AUTOSAR XML (schema 4.0)
standard types defined: float32, float64, sint16, sint32, sint8, uint16, uint32, uint8, void, boolean
package /ImplDataTypes
  4 x impl type, all with category=TYPE_REFERENCE, type-emitter=RTE:
    Impl_MultiStateBtnType: implementation-data-type=uint8
    Impl_SensorPostionType: implementation-data-type=uint32
    Impl_SensorWeightType: implementation-data-type=uint32
    Impl_StepMotorStepType: implementation-data-type=uint8
package /MappingSets
  data type mapping set MappingSet
package /PortInterfaces/ClientServer
  client server interface CsIf_PostionSensor
    operation Opr_GetPostion
      arg Arg_position: type=Impl_SensorPostionType, direction=OUT
  client server interface CsIf_StepMotor
    operation Opr_Move
      arg Arg_step: type=Impl_StepMotorStepType, direction=IN
  client server interface CsIf_WeightSensor
    operation Opr_GetWeight
      arg Arg_Weight: type=Impl_SensorWeightType, direction=OUT
package /PortInterfaces/SenderReceiver
  sender receiver interface SrIf_SeatCtrlBtns
    data DE_HeightBtnState: type=Impl_MultiStateBtnType
    data DE_InclineBtnState: type=Impl_MultiStateBtnType
    data DE_SlideBtnState: type=Impl_MultiStateBtnType
  sender receiver interface SrIf_SeatCtrlData
    data DE_Height: type=uint8
    data DE_Incline: type=uint8
    data DE_Slide: type=uint8
package /SoftwareComponents
  9 x swc implementation, all with programming-language=C, sw-version=1.0.0, vendor-id=255:
    Impl_SWC_HMI: behavior=Ibhv_SWC_HMI
      code-descriptors:
        code Code: artifact-descriptors=autosar-engineering-object={short-label=SWC.c, category=SWSRC}
      resource consumption ResourceConsumption
    Impl_SWC_HeightMotor: behavior=Ibhv_SWC_HeightMotor
      code-descriptors:
        code Code: artifact-descriptors=autosar-engineering-object={short-label=SWC.c, category=SWSRC}
      resource consumption ResourceConsumption
    Impl_SWC_HeightSensor: behavior=Ibhv_SWC_HeightSensor
      code-descriptors:
        code Code: artifact-descriptors=autosar-engineering-object={short-label=SWC.c, category=SWSRC}
      resource consumption ResourceConsumption
    Impl_SWC_InclineMotor: behavior=Ibhv_SWC_InclineMotor
      code-descriptors:
        code Code: artifact-descriptors=autosar-engineering-object={short-label=SWC.c, category=SWSRC}
      resource consumption ResourceConsumption
    Impl_SWC_InclineSensor: behavior=Ibhv_SWC_InclineSensor
      code-descriptors:
        code Code: artifact-descriptors=autosar-engineering-object={short-label=SWC.c, category=SWSRC}
      resource consumption ResourceConsumption
    Impl_SWC_Seat_Manger: behavior=Ibhv_SWC_Seat_Manger
      code-descriptors:
        code Code: artifact-descriptors=autosar-engineering-object={short-label=SWC.c, category=SWSRC}
      resource consumption ResourceConsumption
    Impl_SWC_SlideMotor: behavior=Ibhv_SWC_SlideMotor
      code-descriptors:
        code Code: artifact-descriptors=autosar-engineering-object={short-label=SWC.c, category=SWSRC}
      resource consumption ResourceConsumption
    Impl_SWC_SlideSensor: behavior=Ibhv_SWC_SlideSensor
      code-descriptors:
        code Code: artifact-descriptors=autosar-engineering-object={short-label=SWC.c, category=SWSRC}
      resource consumption ResourceConsumption
    Impl_SWC_WeightSensor: behavior=Ibhv_SWC_WeightSensor
      code-descriptors:
        code Code: artifact-descriptors=autosar-engineering-object={short-label=SWC.c, category=SWSRC}
      resource consumption ResourceConsumption
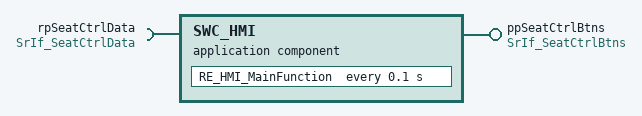
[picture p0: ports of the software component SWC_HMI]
  application sw component type SWC_HMI
    provide port ppSeatCtrlBtns: provided-interface=SrIf_SeatCtrlBtns
    require port rpSeatCtrlData: required-interface=SrIf_SeatCtrlData
    behavior Ibhv_SWC_HMI: data-type-mapping=MappingSet, handle-termination-and-restart=NO-SUPPORT
      timing event TE_RE_HMI_MainFunction_100ms: start-on-event=RE_HMI_MainFunction, period=0.1
      runnable RE_HMI_MainFunction
        data-receive-point-by-arguments:
          access DRP_rpSeatCtrlData_DE_Height: accessed-variable=rpSeatCtrlData.DE_Height
          access DRP_rpSeatCtrlData_DE_Incline: accessed-variable=rpSeatCtrlData.DE_Incline
          access DRP_rpSeatCtrlData_DE_Slide: accessed-variable=rpSeatCtrlData.DE_Slide
        data-send-points:
          access DSP_ppSeatCtrlBtns_DE_HeightBtnState: accessed-variable=ppSeatCtrlBtns.DE_HeightBtnState
          access DSP_ppSeatCtrlBtns_DE_InclineBtnState: accessed-variable=ppSeatCtrlBtns.DE_InclineBtnState
          access DSP_ppSeatCtrlBtns_DE_SlideBtnState: accessed-variable=ppSeatCtrlBtns.DE_SlideBtnState
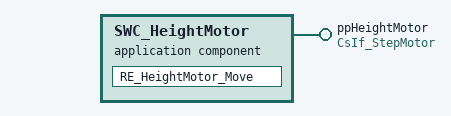
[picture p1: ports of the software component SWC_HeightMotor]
  application sw component type SWC_HeightMotor
    provide port ppHeightMotor: provided-interface=CsIf_StepMotor
    behavior Ibhv_SWC_HeightMotor: data-type-mapping=MappingSet, handle-termination-and-restart=NO-SUPPORT
      operation invoked event OIE_ppHeightMotor_Opr_Move: start-on-event=RE_HeightMotor_Move, operation=ppHeightMotor.Opr_Move
      runnable RE_HeightMotor_Move
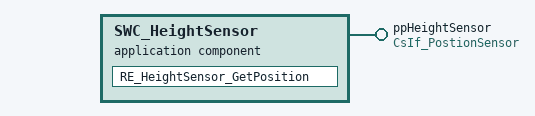
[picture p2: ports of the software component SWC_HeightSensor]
  application sw component type SWC_HeightSensor
    provide port ppHeightSensor: provided-interface=CsIf_PostionSensor
    behavior Ibhv_SWC_HeightSensor: data-type-mapping=MappingSet, handle-termination-and-restart=NO-SUPPORT
      operation invoked event OIE_ppHeightSensor_Opr_GetPostion: start-on-event=RE_HeightSensor_GetPosition, operation=ppHeightSensor.Opr_GetPostion
      runnable RE_HeightSensor_GetPosition
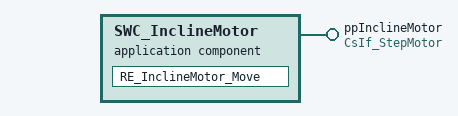
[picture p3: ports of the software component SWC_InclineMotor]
  application sw component type SWC_InclineMotor
    provide port ppInclineMotor: provided-interface=CsIf_StepMotor
    behavior Ibhv_SWC_InclineMotor: data-type-mapping=MappingSet, handle-termination-and-restart=NO-SUPPORT
      operation invoked event OIE_ppInclineMotor_Opr_Move: start-on-event=RE_InclineMotor_Move, operation=ppInclineMotor.Opr_Move
      runnable RE_InclineMotor_Move
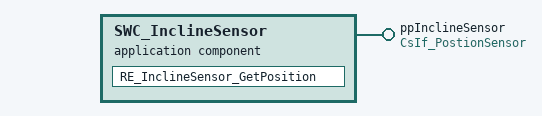
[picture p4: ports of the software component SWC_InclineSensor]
  application sw component type SWC_InclineSensor
    provide port ppInclineSensor: provided-interface=CsIf_PostionSensor
    behavior Ibhv_SWC_InclineSensor: data-type-mapping=MappingSet, handle-termination-and-restart=NO-SUPPORT
      operation invoked event OIE_ppInclineSensor_Opr_GetPostion: start-on-event=RE_InclineSensor_GetPosition, operation=ppInclineSensor.Opr_GetPostion
      runnable RE_InclineSensor_GetPosition
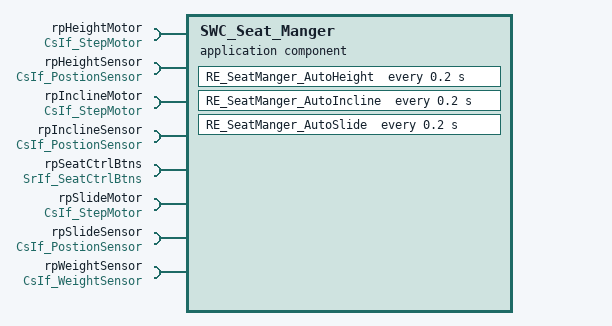
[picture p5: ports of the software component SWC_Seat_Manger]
  application sw component type SWC_Seat_Manger
    8 x require port:
      rpHeightMotor: required-interface=CsIf_StepMotor
      rpHeightSensor: required-interface=CsIf_PostionSensor
      rpInclineMotor: required-interface=CsIf_StepMotor
      rpInclineSensor: required-interface=CsIf_PostionSensor
      rpSeatCtrlBtns: required-interface=SrIf_SeatCtrlBtns
      rpSlideMotor: required-interface=CsIf_StepMotor
      rpSlideSensor: required-interface=CsIf_PostionSensor
      rpWeightSensor: required-interface=CsIf_WeightSensor
    behavior Ibhv_SWC_Seat_Manger: data-type-mapping=MappingSet, handle-termination-and-restart=NO-SUPPORT
      data received event DRE_rpSeatCtrlBtns_DE_HeightBtnState: start-on-event=RE_SeatManger_SetHeight, data=rpSeatCtrlBtns.DE_HeightBtnState
      data received event DRE_rpSeatCtrlBtns_DE_InclineBtnState: start-on-event=RE_SeatManger_SetIncline, data=rpSeatCtrlBtns.DE_InclineBtnState
      data received event DRE_rpSeatCtrlBtns_DE_SlideBtnState: start-on-event=RE_SeatManger_SetSlide, data=rpSeatCtrlBtns.DE_SlideBtnState
      timing event TE_RE_SeatManger_AutoHeight_200ms: start-on-event=RE_SeatManger_AutoHeight, period=0.2
      timing event TE_RE_SeatManger_AutoIncline_200ms: start-on-event=RE_SeatManger_AutoIncline, period=0.2
      timing event TE_RE_SeatManger_AutoSlide_200ms: start-on-event=RE_SeatManger_AutoSlide, period=0.2
      6 x runnable:
        RE_SeatManger_AutoHeight
          sync call SCP_rpHeightMotor_Opr_Move: operation=rpHeightMotor.Opr_Move, timeout=0.0
          sync call SCP_rpHeightSensor_Opr_GetPostion: operation=rpHeightSensor.Opr_GetPostion, timeout=0.0
          sync call SCP_rpWeightSensor_Opr_GetWeight: operation=rpWeightSensor.Opr_GetWeight, timeout=0.0
        RE_SeatManger_AutoIncline
          sync call SCP_rpInclineMotor_Opr_Move: operation=rpInclineMotor.Opr_Move, timeout=0.0
          sync call SCP_rpInclineSensor_Opr_GetPostion: operation=rpInclineSensor.Opr_GetPostion, timeout=0.0
          sync call SCP_rpWeightSensor_Opr_GetWeight: operation=rpWeightSensor.Opr_GetWeight, timeout=0.0
        RE_SeatManger_AutoSlide
          sync call SCP_rpSlideMotor_Opr_Move: operation=rpSlideMotor.Opr_Move, timeout=0.0
          sync call SCP_rpSlideSensor_Opr_GetPostion: operation=rpSlideSensor.Opr_GetPostion, timeout=0.0
          sync call SCP_rpWeightSensor_Opr_GetWeight: operation=rpWeightSensor.Opr_GetWeight, timeout=0.0
        RE_SeatManger_SetHeight
          data-receive-point-by-arguments:
            access DRP_rpSeatCtrlBtns_DE_HeightBtnState: accessed-variable=rpSeatCtrlBtns.DE_HeightBtnState
          sync call SCP_rpHeightMotor_Opr_Move: operation=rpHeightMotor.Opr_Move, timeout=0.0
        RE_SeatManger_SetIncline
          data-receive-point-by-arguments:
            access DRP_rpSeatCtrlBtns_DE_InclineBtnState: accessed-variable=rpSeatCtrlBtns.DE_InclineBtnState
          sync call SCP_rpInclineMotor_Opr_Move: operation=rpInclineMotor.Opr_Move, timeout=0.0
        RE_SeatManger_SetSlide
          data-receive-point-by-arguments:
            access DRP_rpSeatCtrlBtns_DE_SlideBtnState: accessed-variable=rpSeatCtrlBtns.DE_SlideBtnState
          sync call SCP_rpSlideMotor_Opr_Move: operation=rpSlideMotor.Opr_Move, timeout=0.0
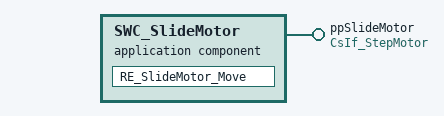
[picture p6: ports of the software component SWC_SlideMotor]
  application sw component type SWC_SlideMotor
    provide port ppSlideMotor: provided-interface=CsIf_StepMotor
    behavior Ibhv_SWC_SlideMotor: data-type-mapping=MappingSet, handle-termination-and-restart=NO-SUPPORT
      operation invoked event OIE_ppSlideMotor_Opr_Move: start-on-event=RE_SlideMotor_Move, operation=ppSlideMotor.Opr_Move
      runnable RE_SlideMotor_Move
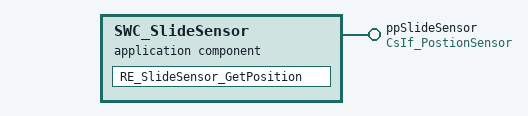
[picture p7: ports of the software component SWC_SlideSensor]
  application sw component type SWC_SlideSensor
    provide port ppSlideSensor: provided-interface=CsIf_PostionSensor
    behavior Ibhv_SWC_SlideSensor: data-type-mapping=MappingSet, handle-termination-and-restart=NO-SUPPORT
      operation invoked event OIE_ppSlideSensor_Opr_GetPostion: start-on-event=RE_SlideSensor_GetPosition, operation=ppSlideSensor.Opr_GetPostion
      runnable RE_SlideSensor_GetPosition
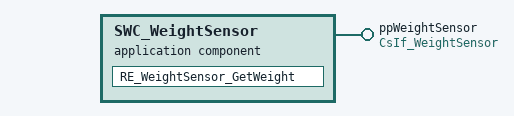
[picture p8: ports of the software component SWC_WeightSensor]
  application sw component type SWC_WeightSensor
    provide port ppWeightSensor: provided-interface=CsIf_WeightSensor
    behavior Ibhv_SWC_WeightSensor: data-type-mapping=MappingSet, handle-termination-and-restart=NO-SUPPORT
      operation invoked event OIE_ppWeightSensor_Opr_GetWeight: start-on-event=RE_WeightSensor_GetWeight, operation=ppWeightSensor.Opr_GetWeight
      runnable RE_WeightSensor_GetWeight
package /Compositions
  composition sw component type SeatAdjManger_task2_AutoSAR_SprintsComposition
    5 x component:
      SWC_HMI: type=SWC_HMI
      SWC_HeightMotor: type=SWC_HeightMotor
      SWC_InclineMotor: type=SWC_InclineMotor
      SWC_Seat_Manger: type=SWC_Seat_Manger
      SWC_SlideMotor: type=SWC_SlideMotor
    connect SWC_HMI.ppSeatCtrlBtns -> SWC_Seat_Manger.rpSeatCtrlBtns
    connect SWC_HeightMotor.ppHeightMotor -> SWC_Seat_Manger.rpHeightMotor
    connect SWC_InclineMotor.ppInclineMotor -> SWC_Seat_Manger.rpInclineMotor
    connect SWC_SlideMotor.ppSlideMotor -> SWC_Seat_Manger.rpSlideMotor
